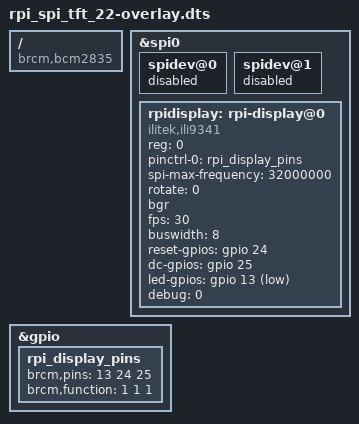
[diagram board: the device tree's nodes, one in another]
/*
 * Device Tree overlay for no name 2.2" SPI TFT
 * adjusted version of https://github.com/philenotfound/rpi_elecfreaks_22_tft_dt_overlay/blob/master/elecfreaks_22_tft.dts
 *
 */

/dts-v1/;
/plugin/;

/ {
	compatible = "brcm,bcm2835";

	fragment@0 {
		target = <&spi0>;
		__overlay__ {
			status = "okay";

			spidev@0{
				status = "disabled";
			};

			spidev@1{
				status = "disabled";
			};
		};
	};

	fragment@1 {
		target = <&gpio>;
		__overlay__ {
			rpi_display_pins: rpi_display_pins {
				brcm,pins = <13 24 25>;
				brcm,function = <1 1 1>; /* out out out */
			};
		};
	};

	fragment@2 {
		target = <&spi0>;
		__overlay__ {
			/* needed to avoid dtc warning */
			#address-cells = <1>;
			#size-cells = <0>;

			rpidisplay: rpi-display@0{
				compatible = "ilitek,ili9341";
				reg = <0>;
				pinctrl-names = "default";
				pinctrl-0 = <&rpi_display_pins>;

				spi-max-frequency = <32000000>;
				rotate = <0>;
				bgr;
				fps = <30>;
				buswidth = <8>;
				reset-gpios = <&gpio 24 0>;
				dc-gpios = <&gpio 25 0>;
				led-gpios = <&gpio 13 1>;
				debug = <0>;
			};
		};
	};
	__overrides__ {
		speed =   <&rpidisplay>,"spi-max-frequency:0";
		rotate =  <&rpidisplay>,"rotate:0";
		fps =     <&rpidisplay>,"fps:0";
		debug =   <&rpidisplay>,"debug:0";
	};
};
